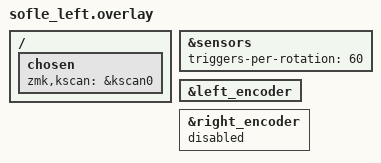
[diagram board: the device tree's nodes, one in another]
/ {
    chosen {
        zmk,kscan = &kscan0;
    };
};

/* Override the sensors node to change triggers-per-rotation */
&sensors {
    triggers-per-rotation = <60>; /* Change from default 20 to 60 */
};

/* Ensure left encoder is enabled on left half */
&left_encoder {
    status = "okay";
};

/* Ensure right encoder is disabled on left half */
&right_encoder {
    status = "disabled";
};
